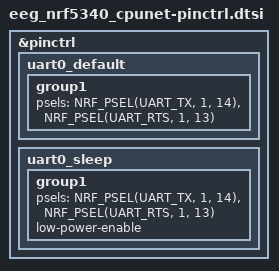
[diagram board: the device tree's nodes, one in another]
/*
 * Copyright (c) 2022 Nordic Semiconductor
 * SPDX-License-Identifier: Apache-2.0
 */

&pinctrl {
	uart0_default: uart0_default {
		group1 {
			psels = <NRF_PSEL(UART_TX, 1, 14)>,
				    <NRF_PSEL(UART_RTS, 1, 13)>;
		};
	};

	uart0_sleep: uart0_sleep {
		group1 {
			psels = <NRF_PSEL(UART_TX, 1, 14)>,
				    <NRF_PSEL(UART_RTS, 1, 13)>;
			low-power-enable;
		};
	};
};
